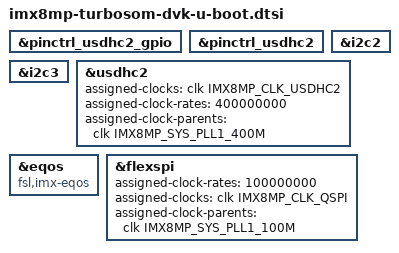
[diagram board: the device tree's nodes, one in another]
#include "imx8mp-turbosom-u-boot.dtsi"

&pinctrl_usdhc2_gpio {
	u-boot,dm-spl;
};

&pinctrl_usdhc2 {
	u-boot,dm-spl;
};

&i2c2 {
	u-boot,dm-spl;
};

&i2c3 {
	u-boot,dm-spl;
};

&usdhc2 {
	u-boot,dm-spl;
	//sd-uhs-sdr104;
	//sd-uhs-ddr50;
	assigned-clocks = <&clk IMX8MP_CLK_USDHC2>;
	assigned-clock-rates = <400000000>;
	assigned-clock-parents = <&clk IMX8MP_SYS_PLL1_400M>;
};

&eqos {
	compatible = "fsl,imx-eqos";
	/delete-property/ assigned-clocks;
	/delete-property/ assigned-clock-parents;
	/delete-property/ assigned-clock-rates;
};

&flexspi {
	assigned-clock-rates = <100000000>;
	assigned-clocks = <&clk IMX8MP_CLK_QSPI>;
	assigned-clock-parents = <&clk IMX8MP_SYS_PLL1_100M>;
};
